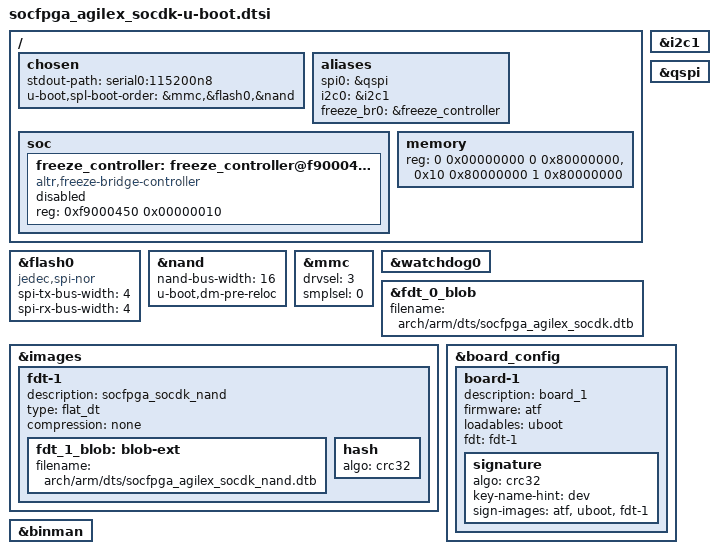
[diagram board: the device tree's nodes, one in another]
// SPDX-License-Identifier: GPL-2.0+
/*
 * U-Boot additions
 *
 * Copyright (C) 2019-2022 Intel Corporation <www.intel.com>
 */

#include "socfpga_agilex-u-boot.dtsi"

/{
	chosen {
		stdout-path = "serial0:115200n8";
		u-boot,spl-boot-order = &mmc,&flash0,&nand;
	};

	aliases {
		spi0 = &qspi;
		i2c0 = &i2c1;
		freeze_br0 = &freeze_controller;
	};

	soc {
		freeze_controller: freeze_controller@f9000450 {
			compatible = "altr,freeze-bridge-controller";
			reg = <0xf9000450 0x00000010>;
			status = "disabled";
		};
	};

	memory {
		/*
		 * Recommended Aliasing addresses
		 *
		 * 16GB
		 *     <0 0x00000000 0 0x80000000>,
		 *     <0x10 0x80000000 3 0x80000000>;
		 *
		 * 8GB
		 *     <0 0x00000000 0 0x80000000>,
		 *     <0x10 0x80000000 1 0x80000000>;
		 *
		 * 4GB
		 *     <0 0x00000000 0 0x80000000>,
		 *     <0x10 0x80000000 0 0x80000000>;
		 *
		 * 2GB
		 *     <0 0x00000000 0 0x80000000>;
		 *
		 * Note: Need to set CONFIG_NR_DRAM_BANKS=1 for 2GB in defconfig
		 *       Default CONFIG_NR_DRAM_BANKS=2 is used for other DDR size
		 */
		reg = <0 0x00000000 0 0x80000000>,
		      <0x10 0x80000000 1 0x80000000>;

	};
};

&flash0 {
	compatible = "jedec,spi-nor";
	spi-tx-bus-width = <4>;
	spi-rx-bus-width = <4>;
	bootph-all;
};

&i2c1 {
	status = "okay";
};

&nand {
	status = "okay";
	nand-bus-width = <16>;
	u-boot,dm-pre-reloc;
};

&mmc {
	drvsel = <3>;
	smplsel = <0>;
	bootph-all;
};

&qspi {
	status = "okay";
};

&watchdog0 {
	bootph-all;
};

#if !defined(CONFIG_SOCFPGA_SECURE_VAB_AUTH)
&fdt_0_blob {
	filename = "arch/arm/dts/socfpga_agilex_socdk.dtb";
};

&images {
	fdt-1 {
		description = "socfpga_socdk_nand";
		type = "flat_dt";
		compression = "none";
		fdt_1_blob: blob-ext {
			filename = "arch/arm/dts/socfpga_agilex_socdk_nand.dtb";
		};
		hash {
			algo = "crc32";
		};
	};
};

&board_config {
	board-1 {
		description = "board_1";
		firmware = "atf";
		loadables = "uboot";
		fdt = "fdt-1";
		signature {
			algo = "crc32";
			key-name-hint = "dev";
			sign-images = "atf", "uboot", "fdt-1";
		};
	};
};

&binman {
	/delete-node/ kernel;
};
#endif

